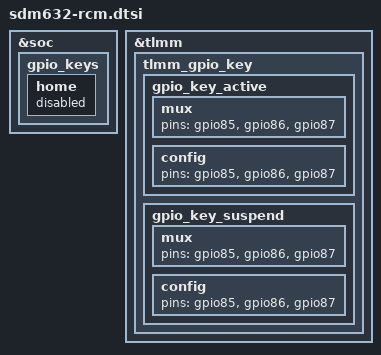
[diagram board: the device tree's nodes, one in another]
/*
 * Copyright (c) 2018, The Linux Foundation. All rights reserved.
 *
 * This program is free software; you can redistribute it and/or modify
 * it under the terms of the GNU General Public License version 2 and
 * only version 2 as published by the Free Software Foundation.
 *
 * This program is distributed in the hope that it will be useful,
 * but WITHOUT ANY WARRANTY; without even the implied warranty of
 * MERCHANTABILITY or FITNESS FOR A PARTICULAR PURPOSE.  See the
 * GNU General Public License for more details.
 */

#include "sdm450-pmi632-cdp-s2.dtsi"

&soc {
	gpio_keys {
		home {
			status = "disabled";
		};
	};
};

&tlmm {
	tlmm_gpio_key {
		gpio_key_active {
			mux {
				pins = "gpio85", "gpio86", "gpio87";
			};

			config {
				pins = "gpio85", "gpio86", "gpio87";
			};
		};

		gpio_key_suspend {
			mux {
				pins = "gpio85", "gpio86", "gpio87";
			};

			config {
				pins = "gpio85", "gpio86", "gpio87";
			};
		};
	};
};
